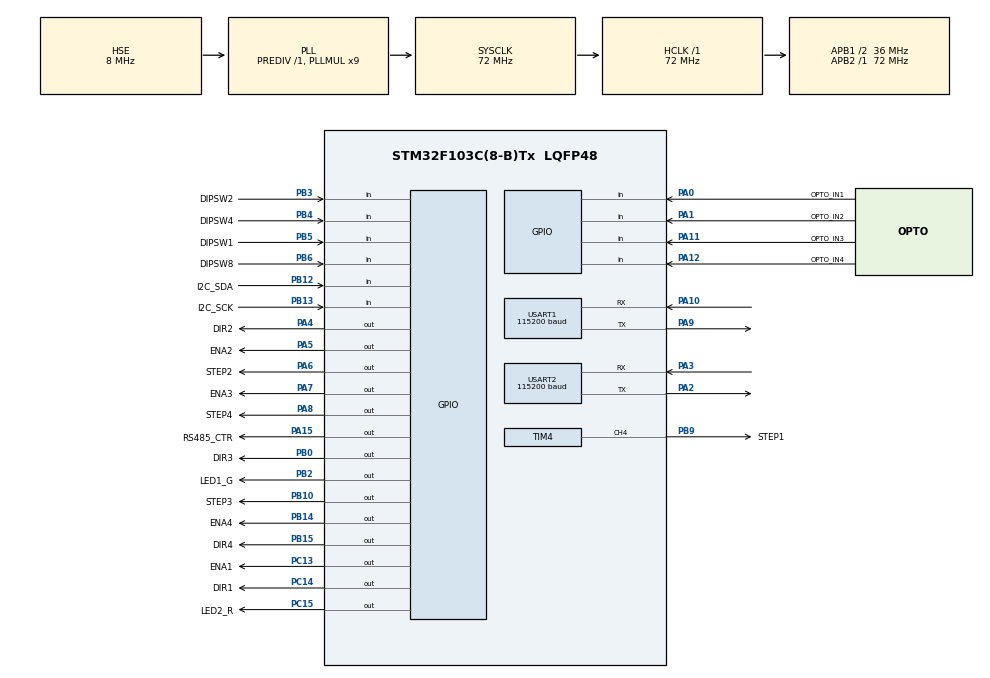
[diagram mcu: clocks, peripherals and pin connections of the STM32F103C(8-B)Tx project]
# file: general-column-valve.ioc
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ADC1.Channel-0\#ChannelRegularConversion=ADC_CHANNEL_TEMPSENSOR
ADC1.ContinuousConvMode=DISABLE
ADC1.DataAlign=ADC_DATAALIGN_RIGHT
ADC1.DiscontinuousConvMode=DISABLE
ADC1.EnableAnalogWatchDog=false
ADC1.EnableInjectedConversion=DISABLE
ADC1.EnableRegularConversion=ENABLE
ADC1.ExternalTrigConv=ADC_SOFTWARE_START
ADC1.Mode=__NULL
ADC1.NbrOfConversion=1
ADC1.Rank-0\#ChannelRegularConversion=1
ADC1.SamplingTime-0\#ChannelRegularConversion=ADC_SAMPLETIME_239CYCLES_5
ADC1.ScanConvMode=ADC_SCAN_DISABLE
ADC1.master=1
Dma.Request0=USART1_TX
Dma.Request1=USART1_RX
Dma.Request2=USART2_TX
Dma.Request3=USART2_RX
Dma.USART1_RX.1.Direction=DMA_PERIPH_TO_MEMORY
Dma.USART1_RX.1.Instance=DMA1_Channel5
Dma.USART1_RX.1.MemDataAlignment=DMA_MDATAALIGN_BYTE
Dma.USART1_RX.1.MemInc=DMA_MINC_ENABLE
Dma.USART1_RX.1.Mode=DMA_NORMAL
Dma.USART1_RX.1.PeriphDataAlignment=DMA_PDATAALIGN_BYTE
Dma.USART1_RX.1.PeriphInc=DMA_PINC_DISABLE
Dma.USART1_RX.1.Priority=DMA_PRIORITY_LOW
Dma.USART1_TX.0.Direction=DMA_MEMORY_TO_PERIPH
Dma.USART1_TX.0.Instance=DMA1_Channel4
Dma.USART1_TX.0.MemDataAlignment=DMA_MDATAALIGN_BYTE
Dma.USART1_TX.0.MemInc=DMA_MINC_ENABLE
Dma.USART1_TX.0.Mode=DMA_NORMAL
Dma.USART1_TX.0.PeriphDataAlignment=DMA_PDATAALIGN_BYTE
Dma.USART1_TX.0.PeriphInc=DMA_PINC_DISABLE
Dma.USART1_TX.0.Priority=DMA_PRIORITY_LOW
Dma.USART2_RX.3.Direction=DMA_PERIPH_TO_MEMORY
Dma.USART2_RX.3.Instance=DMA1_Channel6
Dma.USART2_RX.3.MemDataAlignment=DMA_MDATAALIGN_BYTE
Dma.USART2_RX.3.MemInc=DMA_MINC_ENABLE
Dma.USART2_RX.3.Mode=DMA_NORMAL
Dma.USART2_RX.3.PeriphDataAlignment=DMA_PDATAALIGN_BYTE
Dma.USART2_RX.3.PeriphInc=DMA_PINC_DISABLE
Dma.USART2_RX.3.Priority=DMA_PRIORITY_LOW
Dma.USART2_TX.2.Direction=DMA_MEMORY_TO_PERIPH
Dma.USART2_TX.2.Instance=DMA1_Channel7
Dma.USART2_TX.2.MemDataAlignment=DMA_MDATAALIGN_BYTE
Dma.USART2_TX.2.MemInc=DMA_MINC_ENABLE
Dma.USART2_TX.2.Mode=DMA_NORMAL
Dma.USART2_TX.2.PeriphDataAlignment=DMA_PDATAALIGN_BYTE
Dma.USART2_TX.2.PeriphInc=DMA_PINC_DISABLE
Dma.USART2_TX.2.Priority=DMA_PRIORITY_LOW
Mcu.Family=STM32F1
Mcu.Name=STM32F103C(8-B)Tx
Mcu.Package=LQFP48
NVIC.DMA1_Channel4_IRQn=true\:0\:0\:false\:false\:true\:false\:true\:true
NVIC.DMA1_Channel5_IRQn=true\:0\:0\:false\:false\:true\:false\:true\:true
NVIC.DMA1_Channel6_IRQn=true\:0\:0\:false\:false\:true\:false\:true\:true
NVIC.DMA1_Channel7_IRQn=true\:0\:0\:false\:false\:true\:false\:true\:true
NVIC.PriorityGroup=NVIC_PRIORITYGROUP_4
NVIC.TIM1_CC_IRQn=true\:0\:0\:false\:false\:true\:true\:true\:true
NVIC.USART1_IRQn=true\:1\:0\:true\:false\:true\:true\:true\:true
NVIC.USART2_IRQn=true\:2\:0\:true\:false\:true\:true\:true\:true
PA0-WKUP.GPIO_Label=OPTO_IN1
PA0-WKUP.Signal=GPIO_Input
PA1.GPIO_Label=OPTO_IN2
PA1.Signal=GPIO_Input
PA10.Mode=Asynchronous
PA10.Signal=USART1_RX
PA11.GPIO_Label=OPTO_IN3
PA11.Signal=GPIO_Input
PA12.GPIO_Label=OPTO_IN4
PA12.Signal=GPIO_Input
PA13.Mode=Serial_Wire
PA13.Signal=SYS_JTMS-SWDIO
PA14.Mode=Serial_Wire
PA14.Signal=SYS_JTCK-SWCLK
PA15.GPIO_Label=RS485_CTR
PA15.Signal=GPIO_Output
PA2.Mode=Asynchronous
PA2.Signal=USART2_TX
PA3.Mode=Asynchronous
PA3.Signal=USART2_RX
PA4.GPIO_Label=DIR2
PA4.Signal=GPIO_Output
PA5.GPIO_Label=ENA2
PA5.Signal=GPIO_Output
PA6.GPIO_Label=STEP2
PA6.Signal=GPIO_Output
PA7.GPIO_Label=ENA3
PA7.Signal=GPIO_Output
PA8.GPIO_Label=STEP4
PA8.Signal=GPIO_Output
PA9.Mode=Asynchronous
PA9.Signal=USART1_TX
PB0.GPIO_Label=DIR3
PB0.Signal=GPIO_Output
PB10.GPIO_Label=STEP3
PB10.Signal=GPIO_Output
PB12.GPIO_Label=I2C_SDA
PB12.Signal=GPIO_Input
PB13.GPIO_Label=I2C_SCK
PB13.Signal=GPIO_Input
PB14.GPIO_Label=ENA4
PB14.Signal=GPIO_Output
PB15.GPIO_Label=DIR4
PB15.Signal=GPIO_Output
PB2.GPIO_Label=LED1_G
PB2.Signal=GPIO_Output
PB3.GPIO_Label=DIPSW2
PB3.Signal=GPIO_Input
PB4.GPIO_Label=DIPSW4
PB4.Signal=GPIO_Input
PB5.GPIO_Label=DIPSW1
PB5.Signal=GPIO_Input
PB6.GPIO_Label=DIPSW8
PB6.Signal=GPIO_Input
PB9.GPIO_Label=STEP1
PB9.Signal=S_TIM4_CH4
PC13-TAMPER-RTC.GPIO_Label=ENA1
PC13-TAMPER-RTC.Signal=GPIO_Output
PC14-OSC32_IN.GPIO_Label=DIR1
PC14-OSC32_IN.Signal=GPIO_Output
PC15-OSC32_OUT.GPIO_Label=LED2_R
PC15-OSC32_OUT.Signal=GPIO_Output
PD0-OSC_IN.Mode=HSE-External-Oscillator
PD0-OSC_IN.Signal=RCC_OSC_IN
PD1-OSC_OUT.Mode=HSE-External-Oscillator
PD1-OSC_OUT.Signal=RCC_OSC_OUT
ProjectManager.HeapSize=0x200
ProjectManager.StackSize=0x400
ProjectManager.TargetToolchain=CMake
RCC.ADCPresc=RCC_ADCPCLK2_DIV6
RCC.AHBFreq_Value=72000000
RCC.APB1CLKDivider=RCC_HCLK_DIV2
RCC.APB1Freq_Value=36000000
RCC.APB1TimFreq_Value=72000000
RCC.APB2Freq_Value=72000000
RCC.APB2TimFreq_Value=72000000
RCC.FLatency=FLASH_LATENCY_2
RCC.HCLKFreq_Value=72000000
RCC.PLLMUL=RCC_PLL_MUL9
RCC.PLLSourceVirtual=RCC_PLLSOURCE_HSE
RCC.SYSCLKFreq_VALUE=72000000
RCC.SYSCLKSource=RCC_SYSCLKSOURCE_PLLCLK
RCC.USBFreq_Value=72000000
SH.S_TIM4_CH4.0=TIM4_CH4,PWM Generation4 CH4
TIM1.Channel-Output\ Compare1\ No\ Output=TIM_CHANNEL_1
TIM1.Channel-Output\ Compare2\ No\ Output=TIM_CHANNEL_2
TIM1.Channel-Output\ Compare3\ No\ Output=TIM_CHANNEL_3
TIM1.Channel-Output\ Compare4\ No\ Output=TIM_CHANNEL_4
TIM1.Period=1000-1
TIM1.Prescaler=72-1
TIM1.Pulse-Output\ Compare1\ No\ Output=500-1
TIM1.Pulse-Output\ Compare2\ No\ Output=500-1
TIM1.Pulse-Output\ Compare3\ No\ Output=500-1
TIM1.Pulse-Output\ Compare4\ No\ Output=500-1
TIM2.Period=1000-1
TIM2.Prescaler=72-1
TIM3.Prescaler=72-1
TIM4.AutoReloadPreload=TIM_AUTORELOAD_PRELOAD_DISABLE
TIM4.Channel-PWM\ Generation4\ CH4=TIM_CHANNEL_4
TIM4.ClockDivision=TIM_CLOCKDIVISION_DIV1
TIM4.CounterMode=TIM_COUNTERMODE_UP
TIM4.OC4Preload_PWM=ENABLE
TIM4.OCFastMode_PWM-PWM\ Generation4\ CH4=TIM_OCFAST_DISABLE
TIM4.OCMode_PWM-PWM\ Generation4\ CH4=TIM_OCMODE_PWM1
TIM4.OCPolarity_4=TIM_OCPOLARITY_HIGH
TIM4.Period=1000-1
TIM4.Prescaler=72-1
TIM4.Pulse-PWM\ Generation4\ CH4=0
TIM4.TIM_MasterOutputTrigger=TIM_TRGO_RESET
TIM4.TIM_MasterSlaveMode=TIM_MASTERSLAVEMODE_DISABLE
USART1.BaudRate=115200
USART1.Mode=MODE_TX_RX
USART1.Parity=PARITY_NONE
USART1.StopBits=STOPBITS_1
USART1.VirtualMode=VM_ASYNC
USART1.WordLength=WORDLENGTH_8B
USART2.BaudRate=115200
USART2.Mode=MODE_TX_RX
USART2.Parity=PARITY_NONE
USART2.StopBits=STOPBITS_1
USART2.VirtualMode=VM_ASYNC
USART2.WordLength=WORDLENGTH_8B
VP_ADC1_TempSens_Input.Mode=IN-TempSens
VP_ADC1_Vref_Input.Mode=IN-Vrefint
VP_TIM1_VS_ClockSourceINT.Mode=Internal
VP_TIM1_VS_no_output1.Mode=Output Compare1 No Output
VP_TIM1_VS_no_output2.Mode=Output Compare2 No Output
VP_TIM1_VS_no_output3.Mode=Output Compare3 No Output
VP_TIM1_VS_no_output4.Mode=Output Compare4 No Output
VP_TIM2_VS_ClockSourceINT.Mode=Internal
VP_TIM3_VS_ClockSourceINT.Mode=Internal
VP_TIM4_VS_ClockSourceINT.Mode=Internal
board=custom

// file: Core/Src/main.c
/* USER CODE BEGIN Header */
/**
  ******************************************************************************
  * @file           : main.c
  * @brief          : Main program body
  ******************************************************************************
  * @attention
  *
  * Copyright (c) 2026 STMicroelectronics.
  * All rights reserved.
  *
  * This software is licensed under terms that can be found in the LICENSE file
  * in the root directory of this software component.
  * If no LICENSE file comes with this software, it is provided AS-IS.
  *
  ******************************************************************************
  */
/* USER CODE END Header */
#include "main.h"
#include "adc.h"
#include "dma.h"
#include "tim.h"
#include "usart.h"
#include "gpio.h"

/* USER CODE BEGIN Includes */
// #include "loop.h"
#include "app_main.h"
/* USER CODE END Includes */

void SystemClock_Config(void);

int main(void)
{

  /* MCU Configuration--------------------------------------------------------*/

  /* Reset of all peripherals, Initializes the Flash interface and the Systick. */
  HAL_Init();

  /* Configure the system clock */
  SystemClock_Config();

  /* Initialize all configured peripherals */
  MX_GPIO_Init();
  MX_DMA_Init();
  MX_USART1_UART_Init();
  MX_USART2_UART_Init();
  MX_ADC1_Init();
  MX_TIM4_Init();
  MX_TIM1_Init();
  MX_TIM2_Init();
  MX_TIM3_Init();
  /* USER CODE BEGIN 2 */

  //   loop();
  app_main();

  /* USER CODE END 2 */

  /* Infinite loop */
  while (1)
  {

  }
}

void SystemClock_Config(void)
{
  RCC_OscInitTypeDef RCC_OscInitStruct = {0};
  RCC_ClkInitTypeDef RCC_ClkInitStruct = {0};
  RCC_PeriphCLKInitTypeDef PeriphClkInit = {0};

  /** Initializes the RCC Oscillators according to the specified parameters
  * in the RCC_OscInitTypeDef structure.
  */
  RCC_OscInitStruct.OscillatorType = RCC_OSCILLATORTYPE_HSE;
  RCC_OscInitStruct.HSEState = RCC_HSE_ON;
  RCC_OscInitStruct.HSEPredivValue = RCC_HSE_PREDIV_DIV1;
  RCC_OscInitStruct.HSIState = RCC_HSI_ON;
  RCC_OscInitStruct.PLL.PLLState = RCC_PLL_ON;
  RCC_OscInitStruct.PLL.PLLSource = RCC_PLLSOURCE_HSE;
  RCC_OscInitStruct.PLL.PLLMUL = RCC_PLL_MUL9;
  if (HAL_RCC_OscConfig(&RCC_OscInitStruct) != HAL_OK)
  {
    Error_Handler();
  }

  /** Initializes the CPU, AHB and APB buses clocks
  */
  RCC_ClkInitStruct.ClockType = RCC_CLOCKTYPE_HCLK|RCC_CLOCKTYPE_SYSCLK
                              |RCC_CLOCKTYPE_PCLK1|RCC_CLOCKTYPE_PCLK2;
  RCC_ClkInitStruct.SYSCLKSource = RCC_SYSCLKSOURCE_PLLCLK;
  RCC_ClkInitStruct.AHBCLKDivider = RCC_SYSCLK_DIV1;
  RCC_ClkInitStruct.APB1CLKDivider = RCC_HCLK_DIV2;
  RCC_ClkInitStruct.APB2CLKDivider = RCC_HCLK_DIV1;

  if (HAL_RCC_ClockConfig(&RCC_ClkInitStruct, FLASH_LATENCY_2) != HAL_OK)
  {
    Error_Handler();
  }
  PeriphClkInit.PeriphClockSelection = RCC_PERIPHCLK_ADC;
  PeriphClkInit.AdcClockSelection = RCC_ADCPCLK2_DIV6;
  if (HAL_RCCEx_PeriphCLKConfig(&PeriphClkInit) != HAL_OK)
  {
    Error_Handler();
  }
}

void Error_Handler(void)
{
  __disable_irq();
  while (1)
  {
  }
}
